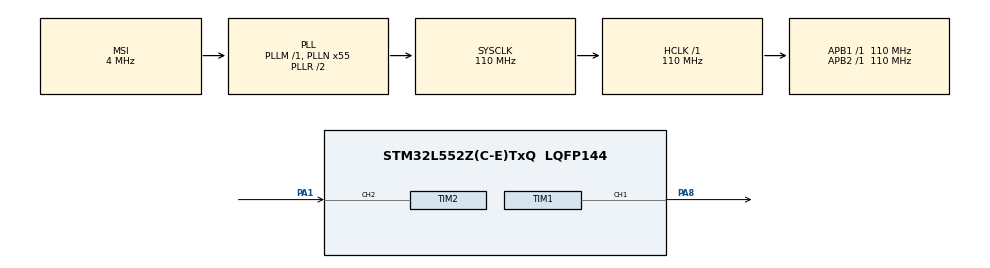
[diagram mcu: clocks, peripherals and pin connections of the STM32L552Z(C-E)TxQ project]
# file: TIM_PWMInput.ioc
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Mcu.Family=STM32L5
Mcu.Name=STM32L552Z(C-E)TxQ
Mcu.Package=LQFP144
NVIC.PriorityGroup=NVIC_PRIORITYGROUP_3
PA1.Signal=S_TIM2_CH2
PA8.Signal=S_TIM1_CH1
ProjectManager.HeapSize=0x200
ProjectManager.StackSize=0x400
ProjectManager.TargetToolchain=EWARM V8.32
RCC.ADCCLockSelection=RCC_ADCCLKSOURCE_SYSCLK
RCC.ADCFreq_Value=110000000
RCC.AHBFreq_Value=110000000
RCC.APB1Freq_Value=110000000
RCC.APB1TimFreq_Value=110000000
RCC.APB2Freq_Value=110000000
RCC.APB2TimFreq_Value=110000000
RCC.CortexFreq_Value=110000000
RCC.DATA_CACHE_ENABLE=0
RCC.HCLKFreq_Value=110000000
RCC.HSE_VALUE=16000000
RCC.HSI48_VALUE=48000000
RCC.HSI_VALUE=16000000
RCC.INSTRUCTION_CACHE_ENABLE=0
RCC.LSE_VALUE=32768
RCC.MSI_VALUE=4000000
RCC.PLLN=55
RCC.PLLSAI1N=24
RCC.RTCClockSelection=RCC_RTCCLKSOURCE_LSE
RCC.SYSCLKFreq_VALUE=110000000
RCC.SYSCLKSource=RCC_SYSCLKSOURCE_PLLCLK
RCC.USBFreq_Value=48000000
RCC.VCOOutputFreq_Value=220000000
SH.S_TIM1_CH1.0=TIM1_CH1,PWM Generation1 CH1
SH.S_TIM2_CH2.0=TIM2_CH2,TriggerSource_TI2FP2
SH.S_TIM2_CH2.1=TIM2_CH2,Input_Capture2_from_TI2
SH.S_TIM2_CH2.2=TIM2_CH2,Input_Capture1_from_TI2
TIM1.AutoReloadPreload=TIM_AUTORELOAD_PRELOAD_DISABLE
TIM1.AutomaticOutput=TIM_AUTOMATICOUTPUT_DISABLE
TIM1.Break2Filter=0
TIM1.Break2Polarity=TIM_BREAK2POLARITY_HIGH
TIM1.Break2State=TIM_BREAK2_DISABLE
TIM1.BreakFilter=0
TIM1.BreakPolarity=TIM_BREAKPOLARITY_HIGH
TIM1.BreakState=TIM_BREAK_DISABLE
TIM1.Channel-PWM\ Generation1\ CH1=TIM_CHANNEL_1
TIM1.ClearInputSource=TIM_CLEARINPUTSOURCE_NONE
TIM1.ClockDivision=TIM_CLOCKDIVISION_DIV1
TIM1.CounterMode=TIM_COUNTERMODE_UP
TIM1.LockLevel=TIM_LOCKLEVEL_OFF
TIM1.OC1Preload_PWM=ENABLE
TIM1.OCFastMode_PWM-PWM\ Generation1\ CH1=TIM_OCFAST_DISABLE
TIM1.OCIdleState_1=TIM_OCIDLESTATE_RESET
TIM1.OCMode_PWM-PWM\ Generation1\ CH1=TIM_OCMODE_PWM1
TIM1.OCPolarity_1=TIM_OCPOLARITY_HIGH
TIM1.OffStateIDLEMode=TIM_OSSI_DISABLE
TIM1.OffStateRunMode=TIM_OSSR_DISABLE
TIM1.Period=(SystemCoreClock/1)/aFrequency[0]
TIM1.Prescaler=uhPrescalerValue
TIM1.Pulse-PWM\ Generation1\ CH1=((SystemCoreClock/1)/aFrequency[0])/aDutyCycle[0]
TIM1.RepetitionCounter=0
TIM1.SourceBRK2COMP1=TIM_BREAKINPUTSOURCE_DISABLE
TIM1.SourceBRK2COMP2=TIM_BREAKINPUTSOURCE_DISABLE
TIM1.SourceBRK2DigInput=TIM_BREAKINPUTSOURCE_DISABLE
TIM1.SourceBRKCOMP1=TIM_BREAKINPUTSOURCE_DISABLE
TIM1.SourceBRKCOMP2=TIM_BREAKINPUTSOURCE_DISABLE
TIM1.SourceBRKDigInput=TIM_BREAKINPUTSOURCE_DISABLE
TIM1.TIM_MasterOutputTrigger=TIM_TRGO_RESET
TIM1.TIM_MasterOutputTrigger2=TIM_TRGO2_RESET
TIM1.TIM_MasterSlaveMode=TIM_MASTERSLAVEMODE_DISABLE
TIM2.AutoReloadPreload=TIM_AUTORELOAD_PRELOAD_DISABLE
TIM2.Channel-Input_Capture1_from_TI2=TIM_CHANNEL_1
TIM2.Channel-Input_Capture2_from_TI2=TIM_CHANNEL_2
TIM2.ClockDivision=TIM_CLOCKDIVISION_DIV1
TIM2.CounterMode=TIM_COUNTERMODE_UP
TIM2.ICFilter_CH2=0
TIM2.ICPolarity_CH1=TIM_INPUTCHANNELPOLARITY_FALLING
TIM2.ICPolarity_CH2=TIM_INPUTCHANNELPOLARITY_RISING
TIM2.ICPrescaler-Input_Capture1_from_TI2=TIM_ICPSC_DIV1
TIM2.ICPrescaler-Input_Capture2_from_TI2=TIM_ICPSC_DIV1
TIM2.ICSelection-Input_Capture1_from_TI2=TIM_ICSELECTION_INDIRECTTI
TIM2.ICSelection-Input_Capture2_from_TI2=TIM_ICSELECTION_DIRECTTI
TIM2.Period=0xFFFF
TIM2.Prescaler=0x0
TIM2.TIM_MasterOutputTrigger=TIM_TRGO_RESET
TIM2.TIM_MasterSlaveMode=TIM_MASTERSLAVEMODE_DISABLE
TIM2.TIM_SlaveMode=TIM_SLAVEMODE_RESET
VP_ICACHE_VS_ICACHE.Mode=DirectMappedCache
VP_PWR_VS_DBSignals.Mode=DisableDeadBatterySignals
VP_TIM2_VS_ControllerModeReset.Mode=Reset Mode
board=custom

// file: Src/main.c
/* USER CODE BEGIN Header */
/**
  ******************************************************************************
  * @file    TIM/TIM_PWMInput/Src/main.c
  * @author  MCD Application Team
  * @brief   This example shows how to use the TIM peripheral to measure the
  *          frequency and duty cycle of an external signal.
  ******************************************************************************
  * @attention
  *
  * Copyright (c) 2019 STMicroelectronics.
  * All rights reserved.
  *
  * This software is licensed under terms that can be found in the LICENSE file
  * in the root directory of this software component.
  * If no LICENSE file comes with this software, it is provided AS-IS.
  *
  ******************************************************************************
  */
/* USER CODE END Header */
#include "main.h"

/* USER CODE BEGIN PD */
/* Number of frequencies */
#define TIM_FREQUENCIES_NB 6
#define TIM_DUTYCYCLE_NB 2
/* USER CODE END PD */

TIM_HandleTypeDef htim1;
TIM_HandleTypeDef htim2;

/* USER CODE BEGIN PV */

/* Captured Value */
__IO uint32_t            uwIC2Value = 0;
/* Duty Cycle Value */
__IO uint32_t            uwDutyCycle = 0;
/* Frequency Value */
__IO uint32_t            uwFrequency = 0;

/* Counter Prescaler value */
uint32_t uhPrescalerValue = 0;

static uint8_t iFrequency = 0;
/* Frequency index *//* Frequency table */
static uint32_t aFrequency[TIM_FREQUENCIES_NB] = {
  2000,   /*  2 kHz */
  2000,   /*  2 kHz */
  3000,   /*  3 kHz */
  3000,   /*  3 kHz */
  4000,   /*  4 kHz */
  4000,   /*  4 kHz */
};
/* Frequency index */

static uint8_t iDutyCycle = 0;
static uint32_t aDutyCycle[TIM_DUTYCYCLE_NB] = {
  2,   /*  50% */
  4,   /*  25% */
};

/* USER CODE END PV */

void SystemClock_Config(void);
static void MX_GPIO_Init(void);
static void MX_ICACHE_Init(void);
static void MX_TIM2_Init(void);
static void MX_TIM1_Init(void);

int main(void)
{
  /* USER CODE BEGIN 1 */

  /* STM32L5xx HAL library initialization:
       - Systick timer is configured by default as source of time base, but user
         can eventually implement his proper time base source (a general purpose
         timer for example or other time source), keeping in mind that Time base
         duration should be kept 1ms since PPP_TIMEOUT_VALUEs are defined and
         handled in milliseconds basis.
       - Set NVIC Group Priority to 3
       - Low Level Initialization
     */

  /* USER CODE END 1 */

  /* MCU Configuration--------------------------------------------------------*/

  /* Reset of all peripherals, Initializes the Flash interface and the Systick. */
  HAL_Init();

  /* USER CODE BEGIN Init */

  /* Configure LED3 */
  BSP_LED_Init(LED3);

  /* USER CODE END Init */

  /* Configure the system clock */
  SystemClock_Config();

  /* USER CODE BEGIN SysInit */

  /* Configure User push-button in Interrupt mode */
  BSP_PB_Init(BUTTON_USER, BUTTON_MODE_EXTI);

  /* USER CODE END SysInit */

  /* Initialize all configured peripherals */
  MX_GPIO_Init();
  MX_ICACHE_Init();
  MX_TIM2_Init();
  MX_TIM1_Init();
  /* USER CODE BEGIN 2 */

 /* Start Input waveform generation */
  if (HAL_TIM_PWM_Start(&htim1, TIM_CHANNEL_1) != HAL_OK)
  {
    /* PWM Generation Error */
    Error_Handler();
  }

  /* Start the Input Capture in interrupt mode  */
  if (HAL_TIM_IC_Start_IT(&htim2, TIM_CHANNEL_2) != HAL_OK)
  {
    /* Starting Error */
    Error_Handler();
  }

  if (HAL_TIM_IC_Start_IT(&htim2, TIM_CHANNEL_1) != HAL_OK)
  {
    /* Starting Error */
    Error_Handler();
  }

  /* USER CODE END 2 */

  /* Infinite loop */
  while (1)
  {

  }
}

void SystemClock_Config(void)
{
  RCC_OscInitTypeDef RCC_OscInitStruct = {0};
  RCC_ClkInitTypeDef RCC_ClkInitStruct = {0};

  /** Configure the main internal regulator output voltage
  */
  if (HAL_PWREx_ControlVoltageScaling(PWR_REGULATOR_VOLTAGE_SCALE0) != HAL_OK)
  {
    Error_Handler();
  }

  /** Initializes the RCC Oscillators according to the specified parameters
  * in the RCC_OscInitTypeDef structure.
  */
  RCC_OscInitStruct.OscillatorType = RCC_OSCILLATORTYPE_MSI;
  RCC_OscInitStruct.MSIState = RCC_MSI_ON;
  RCC_OscInitStruct.MSICalibrationValue = RCC_MSICALIBRATION_DEFAULT;
  RCC_OscInitStruct.MSIClockRange = RCC_MSIRANGE_6;
  RCC_OscInitStruct.PLL.PLLState = RCC_PLL_ON;
  RCC_OscInitStruct.PLL.PLLSource = RCC_PLLSOURCE_MSI;
  RCC_OscInitStruct.PLL.PLLM = 1;
  RCC_OscInitStruct.PLL.PLLN = 55;
  RCC_OscInitStruct.PLL.PLLP = RCC_PLLP_DIV7;
  RCC_OscInitStruct.PLL.PLLQ = RCC_PLLQ_DIV2;
  RCC_OscInitStruct.PLL.PLLR = RCC_PLLR_DIV2;
  if (HAL_RCC_OscConfig(&RCC_OscInitStruct) != HAL_OK)
  {
    Error_Handler();
  }

  /** Initializes the CPU, AHB and APB buses clocks
  */
  RCC_ClkInitStruct.ClockType = RCC_CLOCKTYPE_HCLK|RCC_CLOCKTYPE_SYSCLK
                              |RCC_CLOCKTYPE_PCLK1|RCC_CLOCKTYPE_PCLK2;
  RCC_ClkInitStruct.SYSCLKSource = RCC_SYSCLKSOURCE_PLLCLK;
  RCC_ClkInitStruct.AHBCLKDivider = RCC_SYSCLK_DIV1;
  RCC_ClkInitStruct.APB1CLKDivider = RCC_HCLK_DIV1;
  RCC_ClkInitStruct.APB2CLKDivider = RCC_HCLK_DIV1;

  if (HAL_RCC_ClockConfig(&RCC_ClkInitStruct, FLASH_LATENCY_5) != HAL_OK)
  {
    Error_Handler();
  }
}

static void MX_ICACHE_Init(void)
{

  /** Enable instruction cache in 1-way (direct mapped cache)
  */
  if (HAL_ICACHE_ConfigAssociativityMode(ICACHE_1WAY) != HAL_OK)
  {
    Error_Handler();
  }
  if (HAL_ICACHE_Enable() != HAL_OK)
  {
    Error_Handler();
  }

}

static void MX_TIM1_Init(void)
{

  TIM_MasterConfigTypeDef sMasterConfig = {0};
  TIM_OC_InitTypeDef sConfigOC = {0};
  TIM_BreakDeadTimeConfigTypeDef sBreakDeadTimeConfig = {0};

  htim1.Instance = TIM1;
  htim1.Init.Prescaler = uhPrescalerValue;
  htim1.Init.CounterMode = TIM_COUNTERMODE_UP;
  htim1.Init.Period = (SystemCoreClock/1)/aFrequency[0];
  htim1.Init.ClockDivision = TIM_CLOCKDIVISION_DIV1;
  htim1.Init.RepetitionCounter = 0;
  htim1.Init.AutoReloadPreload = TIM_AUTORELOAD_PRELOAD_DISABLE;
  if (HAL_TIM_PWM_Init(&htim1) != HAL_OK)
  {
    Error_Handler();
  }
  sMasterConfig.MasterOutputTrigger = TIM_TRGO_RESET;
  sMasterConfig.MasterOutputTrigger2 = TIM_TRGO2_RESET;
  sMasterConfig.MasterSlaveMode = TIM_MASTERSLAVEMODE_DISABLE;
  if (HAL_TIMEx_MasterConfigSynchronization(&htim1, &sMasterConfig) != HAL_OK)
  {
    Error_Handler();
  }
  sConfigOC.OCMode = TIM_OCMODE_PWM1;
  sConfigOC.Pulse = ((SystemCoreClock/1)/aFrequency[0])/aDutyCycle[0];
  sConfigOC.OCPolarity = TIM_OCPOLARITY_HIGH;
  sConfigOC.OCNPolarity = TIM_OCNPOLARITY_HIGH;
  sConfigOC.OCFastMode = TIM_OCFAST_DISABLE;
  sConfigOC.OCIdleState = TIM_OCIDLESTATE_RESET;
  sConfigOC.OCNIdleState = TIM_OCNIDLESTATE_RESET;
  if (HAL_TIM_PWM_ConfigChannel(&htim1, &sConfigOC, TIM_CHANNEL_1) != HAL_OK)
  {
    Error_Handler();
  }
  sBreakDeadTimeConfig.OffStateRunMode = TIM_OSSR_DISABLE;
  sBreakDeadTimeConfig.OffStateIDLEMode = TIM_OSSI_DISABLE;
  sBreakDeadTimeConfig.LockLevel = TIM_LOCKLEVEL_OFF;
  sBreakDeadTimeConfig.DeadTime = 0;
  sBreakDeadTimeConfig.BreakState = TIM_BREAK_DISABLE;
  sBreakDeadTimeConfig.BreakPolarity = TIM_BREAKPOLARITY_HIGH;
  sBreakDeadTimeConfig.BreakFilter = 0;
  sBreakDeadTimeConfig.BreakAFMode = TIM_BREAK_AFMODE_INPUT;
  sBreakDeadTimeConfig.Break2State = TIM_BREAK2_DISABLE;
  sBreakDeadTimeConfig.Break2Polarity = TIM_BREAK2POLARITY_HIGH;
  sBreakDeadTimeConfig.Break2Filter = 0;
  sBreakDeadTimeConfig.Break2AFMode = TIM_BREAK_AFMODE_INPUT;
  sBreakDeadTimeConfig.AutomaticOutput = TIM_AUTOMATICOUTPUT_DISABLE;
  if (HAL_TIMEx_ConfigBreakDeadTime(&htim1, &sBreakDeadTimeConfig) != HAL_OK)
  {
    Error_Handler();
  }
  HAL_TIM_MspPostInit(&htim1);

}

static void MX_TIM2_Init(void)
{

  TIM_SlaveConfigTypeDef sSlaveConfig = {0};
  TIM_MasterConfigTypeDef sMasterConfig = {0};
  TIM_IC_InitTypeDef sConfigIC = {0};

  htim2.Instance = TIM2;
  htim2.Init.Prescaler = 0x0;
  htim2.Init.CounterMode = TIM_COUNTERMODE_UP;
  htim2.Init.Period = 0xFFFF;
  htim2.Init.ClockDivision = TIM_CLOCKDIVISION_DIV1;
  htim2.Init.AutoReloadPreload = TIM_AUTORELOAD_PRELOAD_DISABLE;
  if (HAL_TIM_Base_Init(&htim2) != HAL_OK)
  {
    Error_Handler();
  }
  if (HAL_TIM_IC_Init(&htim2) != HAL_OK)
  {
    Error_Handler();
  }
  sSlaveConfig.SlaveMode = TIM_SLAVEMODE_RESET;
  sSlaveConfig.InputTrigger = TIM_TS_TI2FP2;
  sSlaveConfig.TriggerPolarity = TIM_INPUTCHANNELPOLARITY_RISING;
  sSlaveConfig.TriggerFilter = 0;
  if (HAL_TIM_SlaveConfigSynchro(&htim2, &sSlaveConfig) != HAL_OK)
  {
    Error_Handler();
  }
  sMasterConfig.MasterOutputTrigger = TIM_TRGO_RESET;
  sMasterConfig.MasterSlaveMode = TIM_MASTERSLAVEMODE_DISABLE;
  if (HAL_TIMEx_MasterConfigSynchronization(&htim2, &sMasterConfig) != HAL_OK)
  {
    Error_Handler();
  }
  sConfigIC.ICPolarity = TIM_INPUTCHANNELPOLARITY_FALLING;
  sConfigIC.ICSelection = TIM_ICSELECTION_INDIRECTTI;
  sConfigIC.ICPrescaler = TIM_ICPSC_DIV1;
  sConfigIC.ICFilter = 0;
  if (HAL_TIM_IC_ConfigChannel(&htim2, &sConfigIC, TIM_CHANNEL_1) != HAL_OK)
  {
    Error_Handler();
  }
  sConfigIC.ICPolarity = TIM_INPUTCHANNELPOLARITY_RISING;
  sConfigIC.ICSelection = TIM_ICSELECTION_DIRECTTI;
  if (HAL_TIM_IC_ConfigChannel(&htim2, &sConfigIC, TIM_CHANNEL_2) != HAL_OK)
  {
    Error_Handler();
  }

}

static void MX_GPIO_Init(void)
{

  /* GPIO Ports Clock Enable */
  __HAL_RCC_GPIOA_CLK_ENABLE();

}

/* USER CODE BEGIN 4 */

/**
  * @brief EXTI line detection callbacks
  * @param GPIO_Pin: Specifies the pins connected EXTI line
  * @retval None
  */
void UserButton_Callback()
{
    /* Set new PWM signal frequency and duty cycle*/
    iFrequency = (iFrequency + 1) % TIM_FREQUENCIES_NB;
    iDutyCycle = (iDutyCycle + 1) % TIM_DUTYCYCLE_NB;

    /* Set the auto-reload value to have the requested frequency */
    /* Frequency = TIM1CLK / (ARR + 1) = SystemCoreClock / (ARR + 1)  */
    LL_TIM_SetAutoReload(TIM1, __LL_TIM_CALC_ARR(SystemCoreClock/1, LL_TIM_GetPrescaler(TIM1), aFrequency[iFrequency]));

    /* Set  duty cycle */
    LL_TIM_OC_SetCompareCH1(TIM1, (LL_TIM_GetAutoReload(TIM1) / aDutyCycle[iDutyCycle]));

}

/**
  * @brief  Input Capture callback in non blocking mode
  * @param  htim : TIM IC handle
  * @retval None
  */
void TimerCaptureCompare_Ch2_Callback()
{
  /* Get the Input Capture value */
  uwIC2Value = LL_TIM_IC_GetCaptureCH2(TIM2);

  if (uwIC2Value != 0)
  {
    /* Duty cycle computation */
    uwDutyCycle = (LL_TIM_IC_GetCaptureCH1(TIM2) * 100) / uwIC2Value;

    /* uwFrequency computation
    TIM2 freq  = SystemCoreClock */
    uwFrequency = SystemCoreClock  / (1*uwIC2Value);
  }
  else
  {
    uwDutyCycle = 0;
    uwFrequency = 0;
  }
}

/* USER CODE END 4 */

void Error_Handler(void)
{
  /* USER CODE BEGIN Error_Handler_Debug */
  /* User can add his own implementation to report the HAL error return state */
  /* Turn LED3 on */
  BSP_LED_On(LED3);
  while (1)
  {
  }
  /* USER CODE END Error_Handler_Debug */
}

#ifdef  USE_FULL_ASSERT
/**
  * @brief  Reports the name of the source file and the source line number
  *         where the assert_param error has occurred.
  * @param  file: pointer to the source file name
  * @param  line: assert_param error line source number
  * @retval None
  */
void assert_failed(uint8_t *file, uint32_t line)
{
  /* USER CODE BEGIN 6 */
  /* User can add his own implementation to report the file name and line number,
     ex: printf("Wrong parameters value: file %s on line %d\r\n", file, line) */
  /* Infinite loop */
  while (1)
  {}
  /* USER CODE END 6 */
}
#endif /* USE_FULL_ASSERT */
